# IND83212 register map
Series: Verne; File version: B0
CPU: CM0 r0p1, selectable endian, no MPU, no FPU, 4 interrupt priority bits
Registers are 32-bit, read-write, no defined reset value unless marked. A register's access mark holds for its fields unless they carry their own. Offsets are from the block's base; [hi:lo] are bit positions.

## CRGA — Clock & Reset Generator
Base 0x50000000; register names take the prefix CRGA_
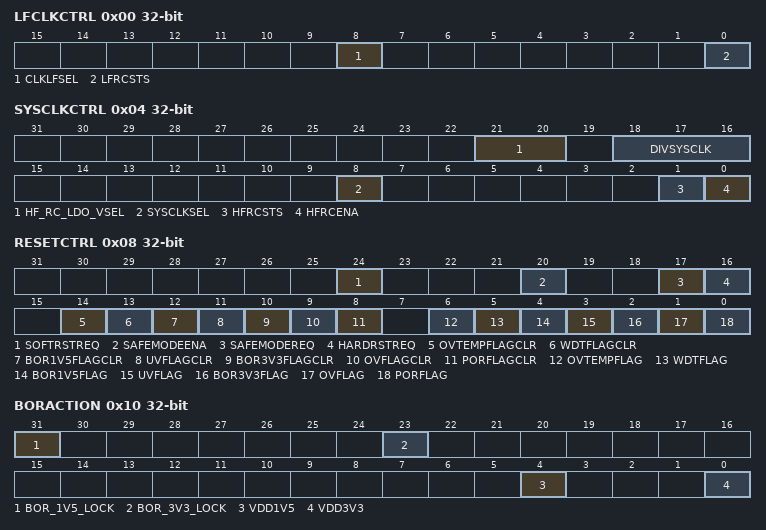
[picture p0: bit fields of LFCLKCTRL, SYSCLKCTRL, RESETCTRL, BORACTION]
0x00 LFCLKCTRL — Low frequency clock control
  [8] CLKLFSEL — LF Clock Source select. Used to select lf osc mode between 0x0: CLK_LF(LF OSC out) is 256KHz, slow system clock freq is Freq_CLK_LF/2 = 128KHz. 0x1: CLK_LF(LF OSC out) is 256KHz, slow system clock freq is Freq_CLK_LF/16= 16KHz.
  [0] LFRCSTS ro — Slow oscillator status. Will be high when the Low Frequency oscillator is selected
0x04 SYSCLKCTRL — System clock control.
  [21:20] HF_RC_LDO_VSEL — 16MHz RC OSC LDO output select. 0x0: 1V45 Selected 0x1: 1V50 Selected 0x2: 1V55 Selected 0x3: 1V65 Selected
  [18:16] DIVSYSCLK — Clock div select. Select the divider ratio on the system clock when using fast oscillator 0x0: No Division. Full Clock speed. 0x1: Div by 2. 0x2: Div by 3. 0x3: Div by 4. 0x4: Div by 5. 0x5: Div by 6. 0x6: Div by 7. 0x7: Div by 8.
  [8] SYSCLKSEL — Clock select. Used to switch between the fast and slow system clocks 0x0: Slow clock 0x1: Fast clock
  [1] HFRCSTS ro — Fast oscillator status. Will be high when High Frequency oscillator is enabled
  [0] HFRCENA — Fast oscillator enable. Setting this bit when the High Frequency oscillator is not running will cause the oscillator to start (the PMU may have already started it). Even though the fast oscillator is running, its output is only used when selected via the clock mux - see CLKSEL. This bit is cleared automatically on entering SLEEP mode
0x08 RESETCTRL — Reset control
  [24] SOFTRSTREQ wo — Soft reset request. Set to trigger a soft reset of chip Autoclear: includes a synchronous reset signal which clears the register on the cycle following write.
  [20] SAFEMODEENA — Safe Mode enable. Set to enable safe Mode.Configure with writting debug key of SYSCTRL_SFRS->DEBUG_ACCESS_KEY.
  [17] SAFEMODEREQ wo — Safe Mode request. Set to force chip into Safe Mode, in which Chip can only be wakeup by POR.Configure with writting debug key of SYSCTRL_SFRS->DEBUG_ACCESS_KEY. Autoclear: includes a synchronous reset signal which clears the register on the cycle following write.
  [16] HARDRSTREQ wo — Hard reset request. Set to trigger a hard reset of chip
  [14] OVTEMPFLAGCLR wo — OVTEMP flag clear. Set to clear the OVTEMP flag
  [13] WDTFLAGCLR wo — WDT flag clear. Set to clear the WDT flag
  [12] BOR1V5FLAGCLR wo — BOR 1v5 clear. Set to clear the 1.5V brownout detected flag
  [11] UVFLAGCLR wo — UV flag clear. Set to clear the UV flag
  [10] BOR3V3FLAGCLR wo — BOR 3v3 clear. Set to clear the 3.3V brownout detected flag
  [9] OVFLAGCLR wo — OV flag clear. Set to clear the OV flag
  [8] PORFLAGCLR wo — POR flag clear. Set to clear the POR flag
  [6] OVTEMPFLAG ro — Over Temp Violation flag. Set by the hardware when the over temp condition is detected.
  [5] WDTFLAG ro — Watchdog bark flag. Set by the hardware when the watchdog barks.
  [4] BOR1V5FLAG ro — BOR 1v5 flag. Set by the hardware when a brownout of the 1.5V supply is detected.
  [3] UVFLAG ro — Under Voltage Monitor flag. Set by the hardware when the under voltage monitor.
  [2] BOR3V3FLAG ro — BOR 3v3 flag. Set by the hardware when a brownout of the 3.3V supply is detected.
  [1] OVFLAG ro — Over Voltage Monitor flag. Set by the hardware when the over voltage monitor.
  [0] PORFLAG ro — Power on reset flag. Set by the hardware during power-on reset
0x0C MODULERST — Module Reset control
  [3:0] MODULERSTREQ wo — Module Soft reset request. Set to trigger a soft reset of module below. 0x1: ADC Soft reset request 0x2: LINS Soft reset request 0x4: PWM soft reset request 0x8: PWM AUX soft reset request Autoclear: includes a synchronous reset signal which clears the register on the cycle following write.
0x10 BORACTION
  [31] BOR_1V5_LOCK — Set Only bit. Set this bit to lock BOR_1V5_ACTION & S_BOR_1V5 bits.
  [23] BOR_3V3_LOCK — Set Only bit. Set this bit to lock BOR_3V3_ACTION & S_BOR_3V3 bits.
  [4] VDD1V5 ro — BOR 1v5 action. Defines the consequences of brown-out condition on the 1v5 supply being detected by the hardware. Configure with writting trim key 0x1: IRQ generated 0x0: Hard reset generated
  [0] VDD3V3 — BOR 3v3 action. Defines the consequences of brown-out condition on the 3v3 supply being detected by the hardware. Configure with writting trim key 0x1: IRQ generated 0x0: Hard reset generated
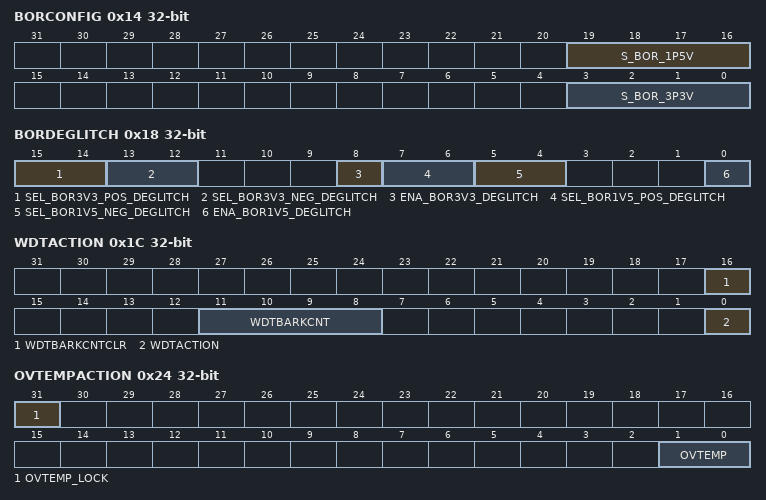
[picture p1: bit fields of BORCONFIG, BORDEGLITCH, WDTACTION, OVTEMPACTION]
0x14 BORCONFIG — BOR configuration
  [19:16] S_BOR_1P5V — BOR 1v5 threshold. Select the BOR threshold voltage level for the 1v5 regulator. Following typical value can be used as reference: NOTE: The write operation of this register takes effect by PMU_SFRS->CTRL.UPDATE and write trim key 0x0: Vr: 1.243 V, Vf: 1.218 V, 0x1: Vr: 1.273 V, Vf: 1.243 V, 0x2: Vr: 1.298 V, Vf: 1.273 V, 0x3: Vr: 1.328 V, Vf: 1.298 V, 0x4: Vr: 1.358 V, Vf: 1.328 V, 0x5: Vr: 1.393 V, Vf: 1.363 V, 0x6: Vr: 1.428 V, Vf: 1.393 V, 0x7: Vr: 1.463 V, Vf: 1.428 V, 0x8: Vr: 1.498 V, Vf: 1.468 V, 0x9: Vr: 1.538 V, Vf: 1.503 V, 0xa: Vr: 1.583 V, Vf: 1.548 V, 0xb: Vr: 1.623 V, Vf: 1.588 V, 0xc: Vr: 1.673 V, Vf: 1.633 V, 0xd: Vr: 1.718 V, Vf: 1.683 V, 0xe: Vr: 1.773 V, Vf: 1.733 V, 0xf: Vr: 1.828 V, Vf: 1.788 V,
  [3:0] S_BOR_3P3V — BOR 3v3 threshold. Select the BOR threshold voltage level for the 3v3 regulator, Following typical value can be used as reference: NOTE: The write operation of this register takes effect by PMU_SFRS->CTRL.UPDATE and write trim key 0x0: Vr: 2.223 V, Vf: 2.163 V, 0x1: Vr: 2.288 V, Vf: 2.228 V, 0x2: Vr: 2.358 V, Vf: 2.293 V, 0x3: Vr: 2.428 V, Vf: 2.363 V, 0x4: Vr: 2.503 V, Vf: 2.433 V, 0x5: Vr: 2.583 V, Vf: 2.513 V, 0x6: Vr: 2.668 V, Vf: 2.598 V, 0x7: Vr: 2.763 V, Vf: 2.688 V, 0x8: Vr: 2.858 V, Vf: 2.783 V, 0x9: Vr: 2.968 V, Vf: 2.883 V, 0xa: Vr: 3.078 V, Vf: 2.998 V, 0xb: Vr: 3.203 V, Vf: 3.118 V, 0xc: Vr: 3.338 V, Vf: 3.248 V, 0xd: Vr: 3.483 V, Vf: 3.388 V, 0xe: Vr: 3.638 V, Vf: 3.543 V, 0xf: Vr: 3.813 V, Vf: 3.708 V,
0x18 BORDEGLITCH — BOR Deglitch, NOTE: The write operation of this register takes effect by PMU_SFRS->CTRL.UPDATE and write trim key
  [15:14] SEL_BOR3V3_POS_DEGLITCH — select the deglitch width of BOR3V3 posedge. 0x0: 16us Selected 0x1: 32us Selected 0x2: 64us Selected 0x3: 128us Selected
  [13:12] SEL_BOR3V3_NEG_DEGLITCH — select the deglitch width of BOR3V3 negedge. 0x0: 16us Selected 0x1: 32us Selected 0x2: 64us Selected 0x3: 128us Selected
  [8] ENA_BOR3V3_DEGLITCH — enable of BOR3V3 deglitch.
  [7:6] SEL_BOR1V5_POS_DEGLITCH — select the deglitch width of BOR1V5 posedge. 0x0: 16us Selected 0x1: 32us Selected 0x2: 64us Selected 0x3: 128us Selected
  [5:4] SEL_BOR1V5_NEG_DEGLITCH — select the deglitch width of BOR1V5 negedge. 0x0: 16us Selected 0x1: 32us Selected 0x2: 64us Selected 0x3: 128us Selected
  [0] ENA_BOR1V5_DEGLITCH — enable of BOR1V5 deglitch.
0x1C WDTACTION — Watchdog action
  [16] WDTBARKCNTCLR wo — WatchDog Bark Counter Clear. Set to clear watchdog bark counter.
  [11:8] WDTBARKCNT ro — WatchDog Bark Counter. Read to reflect the WDT bark counter value.
  [0] WDTACTION — Watchdog action. Defines the consequences of watchdog bark being detected by the hardware. 0x0: IRQ generated 0x1: Hard reset generated
0x20 LFCLKKILL — Low frequency clock kill
  [0] KILLLFRC — Kill slow RC oscillator. Setting this bit gates the low frequency RC oscillator input.Configure with writting debug key of SYSCTRL_SFRS->DEBUG_ACCESS_KEY.
0x24 OVTEMPACTION
  [31] OVTEMP_LOCK — Set Only bit. Set this bit to lock OVTEMP related bits.
  [1:0] OVTEMP — Over Temperature action. Defines the consequences of over temp condition detected by the hardware. 0x2: No action 0x1: IRQ generated 0x0: Hard reset generated
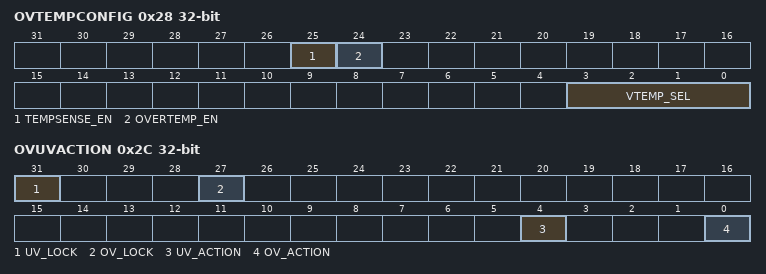
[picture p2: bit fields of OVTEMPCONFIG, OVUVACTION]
0x28 OVTEMPCONFIG — OVTEMP configuration
  [25] TEMPSENSE_EN — enable Temp Sensor Analog Part. Set to enable Temperature Sensor analog circuit. NOTE: The write operation of this register takes effect by IOCTRL_SFRS->LIN.UPDATE
  [24] OVERTEMP_EN — OverTemp Monitor Enable bit.
  [3:0] VTEMP_SEL — Over Temp protect threshold temp trim. Select the OVTEMP threshold level for the monitor.The write operation of this register takes effect by PMU_SFRS->CTRL.UPDATE . 0x0: Rising: 93.13-Deg; Falling: 79.13-Deg 0x1: Rising: 98.13-Deg; Falling: 84.13-Deg 0x2: Rising: 103.6-Deg; Falling: 89.13-Deg 0x3: Rising: 109.1-Deg; Falling: 94.13-Deg 0x4: Rising: 115.1-Deg; Falling: 99.63-Deg 0x5: Rising: 121.1-Deg; Falling: 105.1-Deg 0x6: Rising: 127.1-Deg; Falling: 111.1-Deg 0x7: Rising: 133.1-Deg; Falling: 117.1-Deg 0x8: Rising: 139.6-Deg; Falling: 123.1-Deg 0x9: Rising: 146.6-Deg; Falling: 129.6-Deg 0xa: Rising: 153.6-Deg; Falling: 136.1-Deg 0xb: Rising: 160.6-Deg; Falling: 142.6-Deg 0xc: Rising: 168.1-Deg; Falling: 149.6-Deg 0xd: Rising: 176.6-Deg; Falling: 157.1-Deg 0xe: Rising: 185.1-Deg; Falling: 164.6-Deg 0xf: Rising: 195.6-Deg; Falling: 172.6-Deg
0x2C OVUVACTION
  [31] UV_LOCK — Set Only bit. Set this bit to lock UV ACTION related bits.
  [27] OV_LOCK — Set Only bit. Set this bit to lock OV ACTION related bits.
  [4] UV_ACTION — Under Voltage action. Defines the consequences of under voltage condition detected by the hardware. 0x1: No action 0x0: Hard reset generated
  [0] OV_ACTION — Over Voltage action. Defines the consequences of over voltage condition detected by the hardware. 0x1: No action 0x0: Hard reset generated
